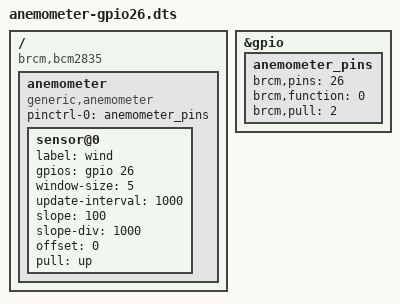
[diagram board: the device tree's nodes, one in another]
// SPDX-License-Identifier: GPL-2.0
// Anemometer Device Tree Overlay for Raspberry Pi
// Example: GPIO 26 with pull-up enabled
//
// Usage:
// 1. Copy to /boot/overlays/anemometer-gpio26.dts
// 2. Compile: sudo dtc -I dts -O dtb -o /boot/overlays/anemometer-gpio26.dtbo /boot/overlays/anemometer-gpio26.dts
// 3. Enable: Add to /boot/config.txt: dtoverlay=anemometer-gpio26
// 4. Reboot

/dts-v1/;
/plugin/;

/ {
	compatible = "brcm,bcm2835";

	/* Fragment to configure GPIO 26 with pull-up */
	fragment@0 {
		target = <&gpio>;
		__overlay__ {
			anemometer_pins: anemometer_pins {
				brcm,pins = <26>;           /* GPIO 26 (Physical Pin 37) */
				brcm,function = <0>;         /* 0 = input */
				brcm,pull = <2>;             /* 2 = pull-up (0=none, 1=down, 2=up) */
			};
		};
	};

	/* Fragment to create anemometer node */
	fragment@1 {
		target-path = "/";
		__overlay__ {
			anemometer {
				compatible = "generic,anemometer";
				status = "okay";
				pinctrl-names = "default";
				pinctrl-0 = <&anemometer_pins>;

				/* Single sensor on GPIO 26 */
				sensor@0 {
					label = "wind";
					/* GPIO_ACTIVE_HIGH = 0, using numeric value */
					gpios = <&gpio 26 0>;
					
					window-size = <5>;
					update-interval = <1000>;
					slope = <100>;
					slope-div = <1000>;
					offset = <0>;
					pull = "up";
				};
			};
		};
	};
};
